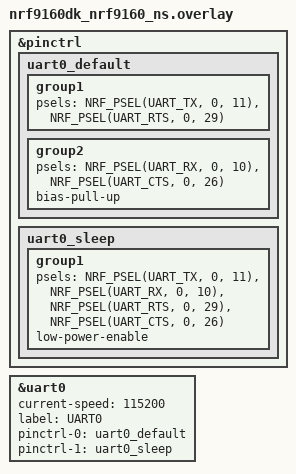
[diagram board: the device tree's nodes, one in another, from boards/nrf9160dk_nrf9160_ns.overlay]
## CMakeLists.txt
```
cmake_minimum_required(VERSION 3.20.0)

find_package(Zephyr REQUIRED HINTS $ENV{ZEPHYR_BASE})
project(ZEPHYR_MQTT_NRF91)

target_sources(app
    PRIVATE
    src/main.c
)

# Add the component LTE
target_sources(app PRIVATE
    components/lte/lte.c)
target_include_directories(app
    PRIVATE
    ${CMAKE_CURRENT_SOURCE_DIR}/components/lte
)

# Add the component MQTT
target_sources(app PRIVATE
    components/mqtt/mqtt.c)
target_include_directories(app
    PRIVATE
    ${CMAKE_CURRENT_SOURCE_DIR}/components/mqtt
)

# Add the component CERTIFICATES
target_sources(app PRIVATE
    components/certs/certs.c)
target_include_directories(app
    PRIVATE
    ${CMAKE_CURRENT_SOURCE_DIR}/components/certs
)
```

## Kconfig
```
menu "MQTT CONFIGURATION"

config MQTT_CLIENT_ID
	string "MQTT Client ID"
	help
	  Use a custom Client ID string. If not set, the client ID will be
	  generated based on IMEI number (for nRF91 Series based targets) or
	  randomly (for other platforms).
	default ""

config MQTT_BROKER_HOSTNAME
	string "MQTT broker hostname"
	default "mqtt.nordicsemi.academy"

config MQTT_BROKER_PORT
	int "MQTT broker port"
	default 1883

config MQTT_MESSAGE_BUFFER_SIZE
	int "MQTT message buffer size"
	default 128

config MQTT_PAYLOAD_BUFFER_SIZE
	int "MQTT payload buffer size"
	default 128

config MQTT_RECONNECT_DELAY_S
	int "Seconds to delay before attempting to reconnect to the broker."
	default 60

config MQTT_TLS_SEC_TAG
	int "TLS credentials security tag"
	default 24

config MQTT_TLS_SESSION_CACHING
	bool "Enable TLS session caching"

config MQTT_TLS_PEER_VERIFY
	int "Set peer verification level"
	default 2
	help
		Set to 0 for VERIFY_NONE, 1 for VERIFY_OPTIONAL, and 2 for
		VERIFY_REQUIRED.

endmenu

source "Kconfig.zephyr"
```

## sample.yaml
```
sample:
  name: nrf91 MQTT zephyr
tests:
  samples.cellular.fundamentals_course:
    build_only: true
    platform_allow: nrf9160dk_nrf9160_ns nrf9151dk_nrf9151_ns nrf9161dk_nrf9161_ns
    integration_platforms:
      - nrf9160dk_nrf9160_ns
      - nrf9151dk_nrf9151_ns
      - nrf9161dk_nrf9161_ns
    tags: ci_build
```

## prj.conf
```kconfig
# Logging
CONFIG_LOG=y

# Newlib
CONFIG_NEWLIB_LIBC=y
CONFIG_NRF_MODEM_LIB=y
CONFIG_NRF_MODEM_LIB_ON_FAULT_RESET_MODEM=y
CONFIG_MODEM_KEY_MGMT=y
CONFIG_MODEM_INFO=y
CONFIG_DATE_TIME=y

# Networking
CONFIG_NETWORKING=y
CONFIG_NET_SOCKETS=y
CONFIG_NET_SOCKETS_POSIX_NAMES=y
CONFIG_NET_IPV4=y
CONFIG_NET_IPV6=y
CONFIG_NET_NATIVE=n
CONFIG_NET_SOCKETS_OFFLOAD=y

# LTE link control
CONFIG_LTE_LINK_CONTROL=y
CONFIG_LTE_AUTO_INIT_AND_CONNECT=n
CONFIG_LTE_NETWORK_MODE_LTE_M=y
CONFIG_LTE_NETWORK_TIMEOUT=180
CONFIG_LTE_NETWORK_USE_FALLBACK=n

# AT Host
CONFIG_UART_INTERRUPT_DRIVEN=y
CONFIG_AT_HOST_LIBRARY=y
CONFIG_CJSON_LIB=y
CONFIG_PDN=y
CONFIG_PDN_ESM_STRERROR=y


# Power Managment
CONFIG_LTE_PSM_REQ=y
CONFIG_LTE_EDRX_REQ=y
CONFIG_LTE_PSM_REQ_RPTAU="00000111"
CONFIG_LTE_PSM_REQ_RAT="00000000"
CONFIG_LTE_EDRX_REQ_VALUE_LTE_M="0010"
CONFIG_LTE_PTW_VALUE_LTE_M="0000"

# Memory
CONFIG_AT_MONITOR_HEAP_SIZE=4096
CONFIG_MAIN_STACK_SIZE=16384
CONFIG_HEAP_MEM_POOL_SIZE=16384
CONFIG_SYSTEM_WORKQUEUE_STACK_SIZE=16384
CONFIG_NEWLIB_LIBC_FLOAT_PRINTF=y


# MQTT
CONFIG_MQTT_LIB=y
CONFIG_MQTT_CLEAN_SESSION=y
CONFIG_MQTT_LIB_TLS=y
CONFIG_MQTT_BROKER_HOSTNAME="a1pex7b5gbosrz-ats.iot.us-east-1.amazonaws.com"
CONFIG_MQTT_BROKER_PORT=8883
CONFIG_MQTT_MESSAGE_BUFFER_SIZE=4096
CONFIG_MQTT_PAYLOAD_BUFFER_SIZE=8192
CONFIG_MQTT_KEEPALIVE=120
CONFIG_MQTT_TLS_SESSION_CACHING=y
CONFIG_MQTT_TLS_SEC_TAG=30
```

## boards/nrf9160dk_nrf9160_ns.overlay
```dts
&pinctrl {
    uart0_default: uart0_default {
        group1 {
            psels = <NRF_PSEL(UART_TX, 0, 11)>,  // Changed pin for UART_TX
                    <NRF_PSEL(UART_RTS, 0, 29)>; 
        };
        group2 {
            psels = <NRF_PSEL(UART_RX, 0, 10)>,  // Changed pin for UART_RX
                    <NRF_PSEL(UART_CTS, 0, 26)>; 
            bias-pull-up;
        };
    };

    uart0_sleep: uart0_sleep {
        group1 {
            psels = <NRF_PSEL(UART_TX, 0, 11)>,  // Changed pin for UART_TX
                    <NRF_PSEL(UART_RX, 0, 10)>,  // Changed pin for UART_RX
                    <NRF_PSEL(UART_RTS, 0, 29)>, 
                    <NRF_PSEL(UART_CTS, 0, 26)>; 
            low-power-enable;
        };
    };
};

&uart0 {
	status = "okay";
	current-speed = <115200>;
    label = "UART0";
	pinctrl-0 = <&uart0_default>;
	pinctrl-1 = <&uart0_sleep>;
	pinctrl-names = "default", "sleep";
};
```

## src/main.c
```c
#include <stdio.h>
#include <ncs_version.h>
#include <zephyr/kernel.h>
#include <zephyr/logging/log.h>
#include "mqtt.h"
#include "lte.h"
#include "certs.h"

LOG_MODULE_REGISTER(MQTT_MAIN);

int main(void)
{
	int err;

	char *MQTT_TEST_SUB_TOPIC = NULL;
	char *MQTT_TEST_PUB_TOPIC = NULL;

	err = write_device_certs_to_modem();
	if (err != 0)
	{
		LOG_ERR("Failed to write certs to modem err [%d]", err);
	}

	err = modem_init();
	if (err != 0)
	{
		LOG_ERR("Failed to init modem err [%d]", err);
	}

	err = lte_init();
	if (err != 0)
	{
		LOG_ERR("Failed to init LTE err [%d]", err);
	}

	err = get_modem_info_imei(DEVICE_ID, DEVICE_ID_SIZE);
	if (err != 0)
	{
		LOG_ERR("Failed to get device id IMEI\n\r");
	}
	LOG_INF("MQTT Device ID IMEI [ %s ]", DEVICE_ID);

	mqtt_create_topic_subscribe(MQTT_TEST_SUB_TOPIC, "mqtt/subscribe/telemetry/%s", DEVICE_ID);
	mqtt_create_topic_subscribe(MQTT_TEST_SUB_TOPIC, "mqtt/subscribe/ota/%s", DEVICE_ID);
	mqtt_create_topic_subscribe(MQTT_TEST_SUB_TOPIC, "mqtt/subscribe/command/%s", DEVICE_ID);

	mqtt_create_topic_publish(MQTT_TEST_PUB_TOPIC, "mqtt/%s/publish/test_topic", DEVICE_ID);

	MQTT_configure();
}
```
